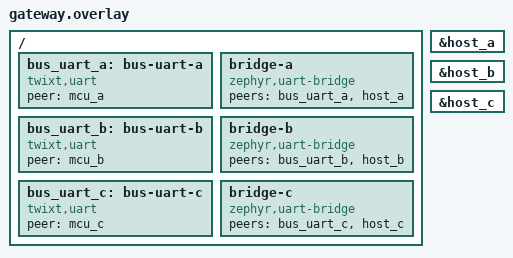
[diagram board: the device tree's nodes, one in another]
/*
 * Copyright (c) 2026 Christoph Jans <jans.christoph@gmail.com>
 *
 * SPDX-License-Identifier: Apache-2.0
 */

/* The console gateway: per board a UART over the bus, bridged to a serial port
 * to the laptop, host_<board>. The board's overlay (boards/) has the host ports,
 * disabled: a PTY on native_sim, USB CDC-ACM on the Raspberry Pi Pico.
 */

/ {
	bus_uart_a: bus-uart-a {
		compatible = "twixt,uart";
		peer = <&mcu_a>;
	};

	bridge-a {
		compatible = "zephyr,uart-bridge";
		peers = <&bus_uart_a &host_a>;
	};

	bus_uart_b: bus-uart-b {
		compatible = "twixt,uart";
		peer = <&mcu_b>;
	};

	bridge-b {
		compatible = "zephyr,uart-bridge";
		peers = <&bus_uart_b &host_b>;
	};

	bus_uart_c: bus-uart-c {
		compatible = "twixt,uart";
		peer = <&mcu_c>;
	};

	bridge-c {
		compatible = "zephyr,uart-bridge";
		peers = <&bus_uart_c &host_c>;
	};
};

&host_a {
	status = "okay";
};

&host_b {
	status = "okay";
};

&host_c {
	status = "okay";
};
